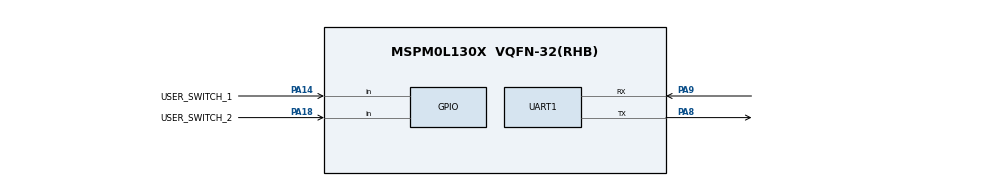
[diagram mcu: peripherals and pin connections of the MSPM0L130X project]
// @cliArgs --device "MSPM0L130X" --package "VQFN-32(RHB)" --part "Default"
// @cliArgs --board /ti/boards/LP_MSPM0L1306 --rtos nortos

/**
 * Import the modules used in this configuration.
 */
const ProjectConfig = scripting.addModule("/ti/project_config/ProjectConfig");
const GPIO   = scripting.addModule("/ti/driverlib/GPIO", {}, false);
const GPIO1  = GPIO.addInstance();
const SYSCTL = scripting.addModule("/ti/driverlib/SYSCTL");
const TIMER  = scripting.addModule("/ti/driverlib/TIMER", {}, false);
const TIMER1 = TIMER.addInstance();
const UART   = scripting.addModule("/ti/driverlib/UART", {}, false);
const UART1  = UART.addInstance();

/**
 * Write custom configuration values to the imported modules.
 */
ProjectConfig.genDisable                 = true;

GPIO1.$name                              = "GPIO_SWITCHES";
GPIO1.port                               = "PORTA";
GPIO1.associatedPins.create(2);
GPIO1.associatedPins[0].$name            = "USER_SWITCH_1";
GPIO1.associatedPins[0].assignedPin      = "14";
GPIO1.associatedPins[0].direction        = "INPUT";
GPIO1.associatedPins[0].internalResistor = "PULL_UP";
GPIO1.associatedPins[0].polarity         = "FALL";
GPIO1.associatedPins[0].interruptEn      = true;
GPIO1.associatedPins[0].pin.$assign      = "PA14";
GPIO1.associatedPins[1].$name            = "USER_SWITCH_2";
GPIO1.associatedPins[1].assignedPin      = "18";
GPIO1.associatedPins[1].direction        = "INPUT";
GPIO1.associatedPins[1].polarity         = "RISE";
GPIO1.associatedPins[1].interruptEn      = true;
GPIO1.associatedPins[1].pin.$assign      = "PA18";

const Board = scripting.addModule("/ti/driverlib/Board", {}, false);

TIMER1.timerMode          = "PERIODIC";
TIMER1.timerPeriod        = "500 ms";
TIMER1.timerClkPrescale   = 256;
TIMER1.interrupts         = ["ZERO"];
TIMER1.$name              = "TIMER";
TIMER1.peripheral.$assign = "TIMG0";

UART1.enabledInterrupts        = ["RX"];
UART1.$name                    = "UART";
UART1.peripheral.$assign       = "UART0";
UART1.peripheral.rxPin.$assign = "PA9";
UART1.peripheral.txPin.$assign = "PA8";
